# STM32MP13xx register map
File version: 1.7
CPU: CA7 r0p0, little endian, MPU, FPU, 4 interrupt priority bits
Registers are 32-bit, read-write, reset 0x0 unless marked. A register's access mark holds for its fields unless they carry their own. Offsets are from the block's base; [hi:lo] are bit positions; {n}, {i} and the like mark numbered series.

## USART1 — Universal synchronous asynchronous receiver transmitter
Base 0x4C000000
Same registers: USART3 0x4000F000, USART4 0x40010000, USART5 0x40011000, USART7 0x40018000, USART8 0x40019000, USART6 0x44003000, USART2 0x4C001000
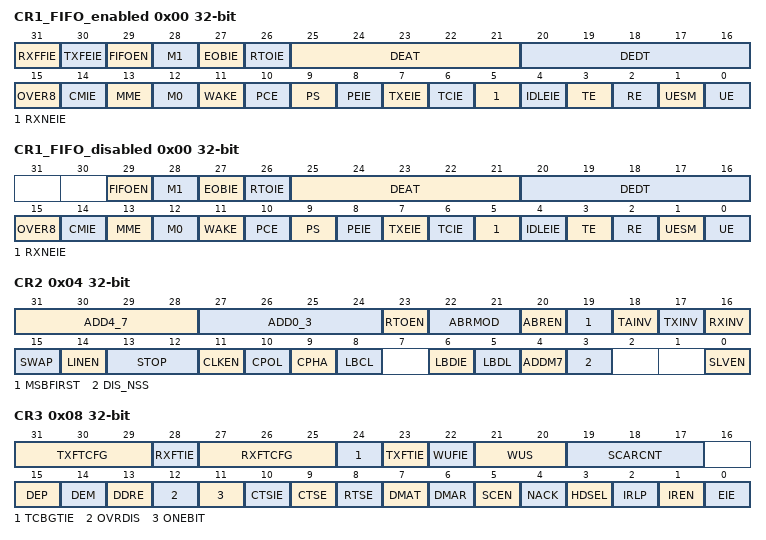
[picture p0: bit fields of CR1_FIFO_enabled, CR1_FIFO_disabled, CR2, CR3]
0x00 CR1_FIFO_enabled — Control register 1
  [31] RXFFIE — RXFIFO Full interrupt enable
  [30] TXFEIE — TXFIFO empty interrupt enable
  [29] FIFOEN — FIFO mode enable
  [28] M1 — Word length
  [27] EOBIE — End of Block interrupt enable
  [26] RTOIE — Receiver timeout interrupt enable
  [25:21] DEAT
  [20:16] DEDT
  [15] OVER8 — Oversampling mode
  [14] CMIE — Character match interrupt enable
  [13] MME — Mute mode enable
  [12] M0 — Word length
  [11] WAKE — Receiver wakeup method
  [10] PCE — Parity control enable
  [9] PS — Parity selection
  [8] PEIE — PE interrupt enable
  [7] TXEIE — interrupt enable
  [6] TCIE — Transmission complete interrupt enable
  [5] RXNEIE — RXNE interrupt enable
  [4] IDLEIE — IDLE interrupt enable
  [3] TE — Transmitter enable
  [2] RE — Receiver enable
  [1] UESM — USART enable in Stop mode
  [0] UE — USART enable
0x00 CR1_FIFO_disabled (alternate view of CR1_FIFO_enabled) — Control register 1
  [29] FIFOEN — FIFO mode enable
  [28] M1 — Word length
  [27] EOBIE — End of Block interrupt enable
  [26] RTOIE — Receiver timeout interrupt enable
  [25:21] DEAT
  [20:16] DEDT
  [15] OVER8 — Oversampling mode
  [14] CMIE — Character match interrupt enable
  [13] MME — Mute mode enable
  [12] M0 — Word length
  [11] WAKE — Receiver wakeup method
  [10] PCE — Parity control enable
  [9] PS — Parity selection
  [8] PEIE — PE interrupt enable
  [7] TXEIE — interrupt enable
  [6] TCIE — Transmission complete interrupt enable
  [5] RXNEIE — RXNE interrupt enable
  [4] IDLEIE — IDLE interrupt enable
  [3] TE — Transmitter enable
  [2] RE — Receiver enable
  [1] UESM — USART enable in Stop mode
  [0] UE — USART enable
0x04 CR2 — Control register 2
  [31:28] ADD4_7 — Address of the USART node
  [27:24] ADD0_3 — Address of the USART node
  [23] RTOEN — Receiver timeout enable
  [22:21] ABRMOD — Auto baud rate mode
  [20] ABREN — Auto baud rate enable
  [19] MSBFIRST — Most significant bit first
  [18] TAINV — Binary data inversion
  [17] TXINV — TX pin active level inversion
  [16] RXINV — RX pin active level inversion
  [15] SWAP — Swap TX/RX pins
  [14] LINEN — LIN mode enable
  [13:12] STOP — STOP bits
  [11] CLKEN — Clock enable
  [10] CPOL — Clock polarity
  [9] CPHA — Clock phase
  [8] LBCL — Last bit clock pulse
  [6] LBDIE — LIN break detection interrupt enable
  [5] LBDL — LIN break detection length
  [4] ADDM7 — 7-bit Address Detection/4-bit Address Detection
  [3] DIS_NSS — When the DSI_NSS bit is set, the NSS pin input will be ignored
  [0] SLVEN — Synchronous Slave mode enable
0x08 CR3 — Control register 3
  [31:29] TXFTCFG — TXFIFO threshold configuration
  [28] RXFTIE — RXFIFO threshold interrupt enable
  [27:25] RXFTCFG — Receive FIFO threshold configuration
  [24] TCBGTIE — Tr Complete before guard time, interrupt enable
  [23] TXFTIE — threshold interrupt enable
  [22] WUFIE — Wakeup from Stop mode interrupt enable
  [21:20] WUS — Wakeup from Stop mode interrupt flag selection
  [19:17] SCARCNT — Smartcard auto-retry count
  [15] DEP — Driver enable polarity selection
  [14] DEM — Driver enable mode
  [13] DDRE — DMA Disable on Reception Error
  [12] OVRDIS — Overrun Disable
  [11] ONEBIT — One sample bit method enable
  [10] CTSIE — CTS interrupt enable
  [9] CTSE — CTS enable
  [8] RTSE — RTS enable
  [7] DMAT — DMA enable transmitter
  [6] DMAR — DMA enable receiver
  [5] SCEN — Smartcard mode enable
  [4] NACK — Smartcard NACK enable
  [3] HDSEL — Half-duplex selection
  [2] IRLP — Ir low-power
  [1] IREN — Ir mode enable
  [0] EIE — Error interrupt enable
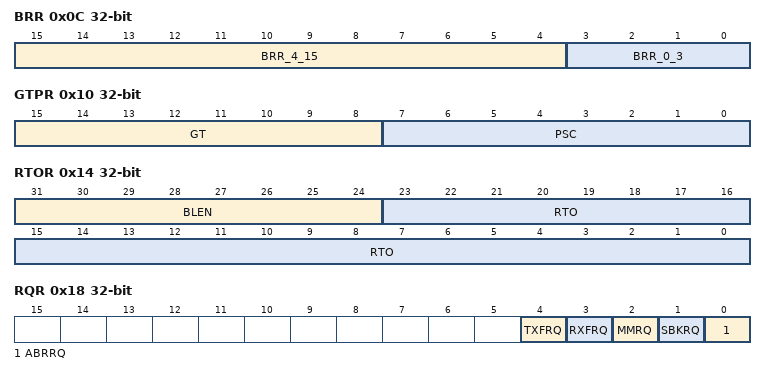
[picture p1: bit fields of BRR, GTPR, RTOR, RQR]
0x0C BRR — Baud rate register
  [15:4] BRR_4_15, [3:0] BRR_0_3
0x10 GTPR — Guard time and prescaler register
  [15:8] GT — Guard time value
  [7:0] PSC — Prescaler value
0x14 RTOR — Receiver timeout register
  [31:24] BLEN — Block Length
  [23:0] RTO — Receiver timeout value
0x18 RQR wo — Request register
  [4] TXFRQ — Transmit data flush request
  [3] RXFRQ — Receive data flush request
  [2] MMRQ — Mute mode request
  [1] SBKRQ — Send break request
  [0] ABRRQ — Auto baud rate request
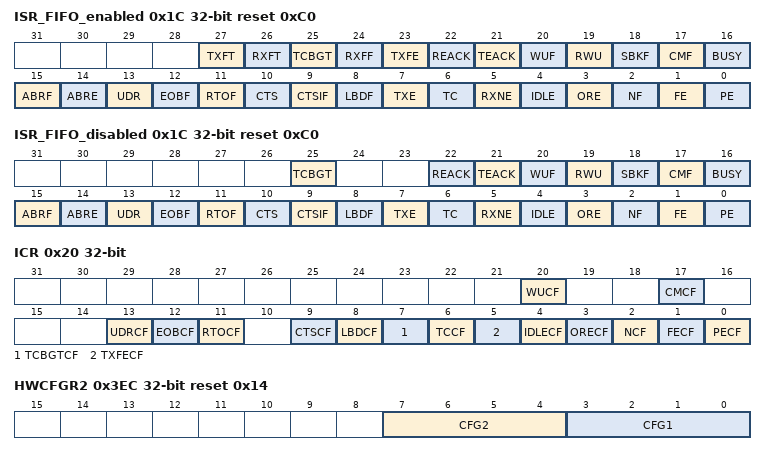
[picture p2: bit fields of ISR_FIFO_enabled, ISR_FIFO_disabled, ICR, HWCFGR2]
0x1C ISR_FIFO_enabled ro reset 0xC0 — USART interrupt and status register
  [27] TXFT — TXFIFO threshold flag
  [26] RXFT — RXFIFO threshold flag
  [25] TCBGT — Transmission complete before guard time flag
  [24] RXFF — RXFIFO Full
  [23] TXFE — TXFIFO Empty
  [22] REACK
  [21] TEACK
  [20] WUF
  [19] RWU
  [18] SBKF
  [17] CMF
  [16] BUSY
  [15] ABRF
  [14] ABRE
  [13] UDR — SPI slave underrun error flag
  [12] EOBF
  [11] RTOF
  [10] CTS
  [9] CTSIF
  [8] LBDF
  [7] TXE
  [6] TC
  [5] RXNE
  [4] IDLE
  [3] ORE
  [2] NF
  [1] FE
  [0] PE
0x1C ISR_FIFO_disabled ro reset 0xC0 (alternate view of ISR_FIFO_enabled) — USART interrupt and status register
  [25] TCBGT — Transmission complete before guard time flag
  [22] REACK
  [21] TEACK
  [20] WUF
  [19] RWU
  [18] SBKF
  [17] CMF
  [16] BUSY
  [15] ABRF
  [14] ABRE
  [13] UDR — SPI slave underrun error flag
  [12] EOBF
  [11] RTOF
  [10] CTS
  [9] CTSIF
  [8] LBDF
  [7] TXE
  [6] TC
  [5] RXNE
  [4] IDLE
  [3] ORE
  [2] NF
  [1] FE
  [0] PE
0x20 ICR wo — Interrupt flag clear register
  [20] WUCF — Wakeup from Stop mode clear flag
  [17] CMCF — Character match clear flag
  [13] UDRCF — SPI slave underrun clear flag
  [12] EOBCF — End of block clear flag
  [11] RTOCF — Receiver timeout clear flag
  [9] CTSCF — CTS clear flag
  [8] LBDCF — LIN break detection clear flag
  [7] TCBGTCF — Transmission complete before Guard time clear flag
  [6] TCCF — Transmission complete clear flag
  [5] TXFECF — TXFIFO empty clear flag
  [4] IDLECF — Idle line detected clear flag
  [3] ORECF — Overrun error clear flag
  [2] NCF — Noise detected clear flag
  [1] FECF — Framing error clear flag
  [0] PECF — Parity error clear flag
0x24 RDR ro — Receive data register
  [8:0] RDR — Receive data value
0x28 TDR — Transmit data register
  [8:0] TDR — Transmit data value
0x2C PRESC — Prescaler register
  [3:0] PRESCALER — Clock prescaler
0x3EC HWCFGR2 ro reset 0x14 — USART Hardware Configuration register 2
  [7:4] CFG2, [3:0] CFG1
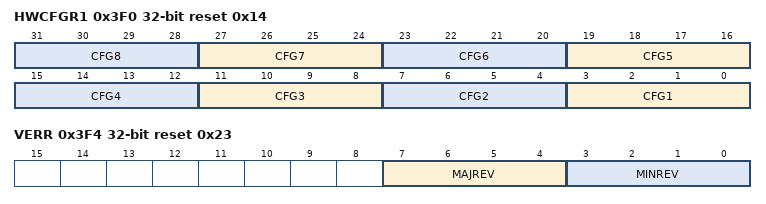
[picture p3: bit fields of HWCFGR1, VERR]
0x3F0 HWCFGR1 ro reset 0x14 — USART Hardware Configuration register 1
  [4n-1:4n-4] CFG{n} (n=1..8)
0x3F4 VERR ro reset 0x23 — EXTI IP Version register
  [7:4] MAJREV — Major Revision number
  [3:0] MINREV — Minor Revision number
0x3F8 IPIDR ro reset 0x130003 — EXTI Identification register
  [31:0] IPID — IP Identification
0x3FC SIDR ro reset 0xA3C5DD01 — EXTI Size ID register
  [31:0] SID — Size Identification
